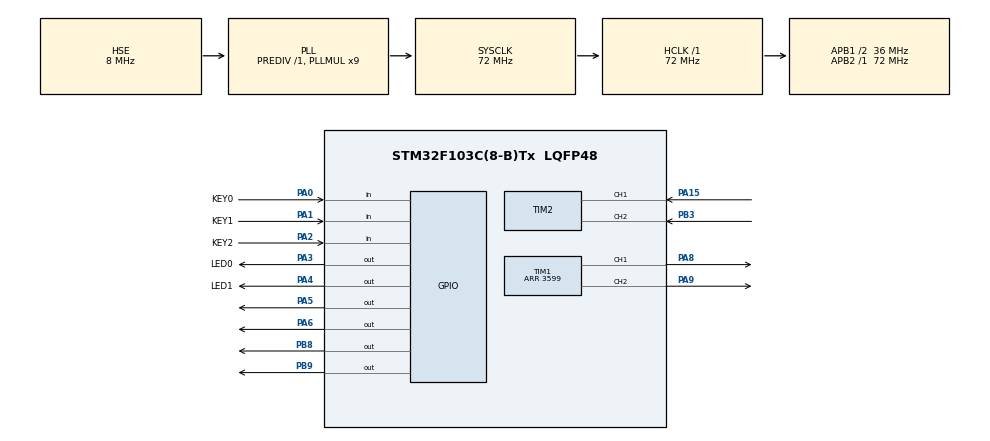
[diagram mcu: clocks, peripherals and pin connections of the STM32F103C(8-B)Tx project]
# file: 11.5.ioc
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Mcu.Family=STM32F1
Mcu.Name=STM32F103C(8-B)Tx
Mcu.Package=LQFP48
NVIC.PriorityGroup=NVIC_PRIORITYGROUP_4
NVIC.TIM3_IRQn=true\:0\:0\:false\:false\:true\:true\:true\:true
NVIC.TIM4_IRQn=true\:1\:0\:true\:false\:true\:true\:true\:true
PA0-WKUP.GPIO_Label=KEY0
PA0-WKUP.GPIO_PuPd=GPIO_PULLUP
PA0-WKUP.Signal=GPIO_Input
PA1.GPIO_Label=KEY1
PA1.GPIO_PuPd=GPIO_PULLUP
PA1.Signal=GPIO_Input
PA13.Mode=Serial_Wire
PA13.Signal=SYS_JTMS-SWDIO
PA14.Mode=Serial_Wire
PA14.Signal=SYS_JTCK-SWCLK
PA15.Signal=S_TIM2_CH1_ETR
PA2.GPIO_Label=KEY2
PA2.GPIO_PuPd=GPIO_PULLUP
PA2.Signal=GPIO_Input
PA3.GPIO_Label=LED0
PA3.PinState=GPIO_PIN_SET
PA3.Signal=GPIO_Output
PA4.GPIO_Label=LED1
PA4.PinState=GPIO_PIN_SET
PA4.Signal=GPIO_Output
PA5.Signal=GPIO_Output
PA6.Signal=GPIO_Output
PA8.Signal=S_TIM1_CH1
PA9.Signal=S_TIM1_CH2
PB3.Signal=S_TIM2_CH2
PB8.GPIO_ModeDefaultOutputPP=GPIO_MODE_OUTPUT_OD
PB8.GPIO_PuPd=GPIO_NOPULL
PB8.GPIO_Speed=GPIO_SPEED_FREQ_LOW
PB8.PinState=GPIO_PIN_SET
PB8.Signal=GPIO_Output
PB9.GPIO_ModeDefaultOutputPP=GPIO_MODE_OUTPUT_OD
PB9.GPIO_PuPd=GPIO_NOPULL
PB9.GPIO_Speed=GPIO_SPEED_FREQ_LOW
PB9.PinState=GPIO_PIN_SET
PB9.Signal=GPIO_Output
PC14-OSC32_IN.Mode=LSE-External-Oscillator
PC14-OSC32_IN.Signal=RCC_OSC32_IN
PC15-OSC32_OUT.Mode=LSE-External-Oscillator
PC15-OSC32_OUT.Signal=RCC_OSC32_OUT
PD0-OSC_IN.Mode=HSE-External-Oscillator
PD0-OSC_IN.Signal=RCC_OSC_IN
PD1-OSC_OUT.Mode=HSE-External-Oscillator
PD1-OSC_OUT.Signal=RCC_OSC_OUT
ProjectManager.HeapSize=0x200
ProjectManager.StackSize=0x400
ProjectManager.TargetToolchain=CMake
RCC.AHBFreq_Value=72000000
RCC.APB1CLKDivider=RCC_HCLK_DIV2
RCC.APB1Freq_Value=36000000
RCC.APB1TimFreq_Value=72000000
RCC.APB2Freq_Value=72000000
RCC.APB2TimFreq_Value=72000000
RCC.HCLKFreq_Value=72000000
RCC.PLLMUL=RCC_PLL_MUL9
RCC.PLLSourceVirtual=RCC_PLLSOURCE_HSE
RCC.SYSCLKFreq_VALUE=72000000
RCC.SYSCLKSource=RCC_SYSCLKSOURCE_PLLCLK
RCC.USBFreq_Value=72000000
SH.S_TIM1_CH1.0=TIM1_CH1,PWM Generation1 CH1
SH.S_TIM1_CH2.0=TIM1_CH2,PWM Generation2 CH2
SH.S_TIM2_CH1_ETR.0=TIM2_CH1,Encoder_Interface
SH.S_TIM2_CH2.0=TIM2_CH2,Encoder_Interface
TIM1.AutoReloadPreload=TIM_AUTORELOAD_PRELOAD_ENABLE
TIM1.Channel-PWM\ Generation1\ CH1=TIM_CHANNEL_1
TIM1.Channel-PWM\ Generation2\ CH2=TIM_CHANNEL_2
TIM1.Period=3599
TIM2.EncoderMode=TIM_ENCODERMODE_TI12
TIM2.IC1Filter=6
TIM3.AutoReloadPreload=TIM_AUTORELOAD_PRELOAD_ENABLE
TIM4.Period=99
TIM4.Prescaler=719
VP_TIM1_VS_ClockSourceINT.Mode=Internal
VP_TIM3_VS_ClockSourceINT.Mode=Internal
VP_TIM4_VS_ClockSourceINT.Mode=Internal
board=custom

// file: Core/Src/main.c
/* USER CODE BEGIN Header */
/**
  ******************************************************************************
  * @file           : main.c
  * @brief          : Main program body
  ******************************************************************************
  * @attention
  *
  * Copyright (c) 2026 STMicroelectronics.
  * All rights reserved.
  *
  * This software is licensed under terms that can be found in the LICENSE file
  * in the root directory of this software component.
  * If no LICENSE file comes with this software, it is provided AS-IS.
  *
  ******************************************************************************
  */
/* USER CODE END Header */
#include "main.h"

TIM_HandleTypeDef htim1;
TIM_HandleTypeDef htim2;
TIM_HandleTypeDef htim3;
TIM_HandleTypeDef htim4;

void SystemClock_Config(void);
static void MX_GPIO_Init(void);
static void MX_TIM1_Init(void);
static void MX_TIM2_Init(void);
static void MX_TIM4_Init(void);
static void MX_TIM3_Init(void);
/* USER CODE BEGIN PFP */
void appMain(void);
/* USER CODE END PFP */

int main(void)
{

  /* MCU Configuration--------------------------------------------------------*/

  /* Reset of all peripherals, Initializes the Flash interface and the Systick. */
  HAL_Init();

  /* Configure the system clock */
  SystemClock_Config();

  /* Initialize all configured peripherals */
  MX_GPIO_Init();
  MX_TIM1_Init();
  MX_TIM2_Init();
  MX_TIM4_Init();
  MX_TIM3_Init();
  /* USER CODE BEGIN 2 */
  appMain();
  /* USER CODE END 2 */

  /* Infinite loop */
  while (1)
  {

  }
}

void SystemClock_Config(void)
{
  RCC_OscInitTypeDef RCC_OscInitStruct = {0};
  RCC_ClkInitTypeDef RCC_ClkInitStruct = {0};

  /** Initializes the RCC Oscillators according to the specified parameters
  * in the RCC_OscInitTypeDef structure.
  */
  RCC_OscInitStruct.OscillatorType = RCC_OSCILLATORTYPE_HSE;
  RCC_OscInitStruct.HSEState = RCC_HSE_ON;
  RCC_OscInitStruct.HSEPredivValue = RCC_HSE_PREDIV_DIV1;
  RCC_OscInitStruct.HSIState = RCC_HSI_ON;
  RCC_OscInitStruct.PLL.PLLState = RCC_PLL_ON;
  RCC_OscInitStruct.PLL.PLLSource = RCC_PLLSOURCE_HSE;
  RCC_OscInitStruct.PLL.PLLMUL = RCC_PLL_MUL9;
  if (HAL_RCC_OscConfig(&RCC_OscInitStruct) != HAL_OK)
  {
    Error_Handler();
  }

  /** Initializes the CPU, AHB and APB buses clocks
  */
  RCC_ClkInitStruct.ClockType = RCC_CLOCKTYPE_HCLK|RCC_CLOCKTYPE_SYSCLK
                              |RCC_CLOCKTYPE_PCLK1|RCC_CLOCKTYPE_PCLK2;
  RCC_ClkInitStruct.SYSCLKSource = RCC_SYSCLKSOURCE_PLLCLK;
  RCC_ClkInitStruct.AHBCLKDivider = RCC_SYSCLK_DIV1;
  RCC_ClkInitStruct.APB1CLKDivider = RCC_HCLK_DIV2;
  RCC_ClkInitStruct.APB2CLKDivider = RCC_HCLK_DIV1;

  if (HAL_RCC_ClockConfig(&RCC_ClkInitStruct, FLASH_LATENCY_2) != HAL_OK)
  {
    Error_Handler();
  }
}

static void MX_TIM1_Init(void)
{

  TIM_ClockConfigTypeDef sClockSourceConfig = {0};
  TIM_MasterConfigTypeDef sMasterConfig = {0};
  TIM_OC_InitTypeDef sConfigOC = {0};
  TIM_BreakDeadTimeConfigTypeDef sBreakDeadTimeConfig = {0};

  htim1.Instance = TIM1;
  htim1.Init.Prescaler = 0;
  htim1.Init.CounterMode = TIM_COUNTERMODE_UP;
  htim1.Init.Period = 3599;
  htim1.Init.ClockDivision = TIM_CLOCKDIVISION_DIV1;
  htim1.Init.RepetitionCounter = 0;
  htim1.Init.AutoReloadPreload = TIM_AUTORELOAD_PRELOAD_ENABLE;
  if (HAL_TIM_Base_Init(&htim1) != HAL_OK)
  {
    Error_Handler();
  }
  sClockSourceConfig.ClockSource = TIM_CLOCKSOURCE_INTERNAL;
  if (HAL_TIM_ConfigClockSource(&htim1, &sClockSourceConfig) != HAL_OK)
  {
    Error_Handler();
  }
  if (HAL_TIM_PWM_Init(&htim1) != HAL_OK)
  {
    Error_Handler();
  }
  sMasterConfig.MasterOutputTrigger = TIM_TRGO_RESET;
  sMasterConfig.MasterSlaveMode = TIM_MASTERSLAVEMODE_DISABLE;
  if (HAL_TIMEx_MasterConfigSynchronization(&htim1, &sMasterConfig) != HAL_OK)
  {
    Error_Handler();
  }
  sConfigOC.OCMode = TIM_OCMODE_PWM1;
  sConfigOC.Pulse = 0;
  sConfigOC.OCPolarity = TIM_OCPOLARITY_HIGH;
  sConfigOC.OCNPolarity = TIM_OCNPOLARITY_HIGH;
  sConfigOC.OCFastMode = TIM_OCFAST_DISABLE;
  sConfigOC.OCIdleState = TIM_OCIDLESTATE_RESET;
  sConfigOC.OCNIdleState = TIM_OCNIDLESTATE_RESET;
  if (HAL_TIM_PWM_ConfigChannel(&htim1, &sConfigOC, TIM_CHANNEL_1) != HAL_OK)
  {
    Error_Handler();
  }
  if (HAL_TIM_PWM_ConfigChannel(&htim1, &sConfigOC, TIM_CHANNEL_2) != HAL_OK)
  {
    Error_Handler();
  }
  sBreakDeadTimeConfig.OffStateRunMode = TIM_OSSR_DISABLE;
  sBreakDeadTimeConfig.OffStateIDLEMode = TIM_OSSI_DISABLE;
  sBreakDeadTimeConfig.LockLevel = TIM_LOCKLEVEL_OFF;
  sBreakDeadTimeConfig.DeadTime = 0;
  sBreakDeadTimeConfig.BreakState = TIM_BREAK_DISABLE;
  sBreakDeadTimeConfig.BreakPolarity = TIM_BREAKPOLARITY_HIGH;
  sBreakDeadTimeConfig.AutomaticOutput = TIM_AUTOMATICOUTPUT_DISABLE;
  if (HAL_TIMEx_ConfigBreakDeadTime(&htim1, &sBreakDeadTimeConfig) != HAL_OK)
  {
    Error_Handler();
  }
  HAL_TIM_MspPostInit(&htim1);

}

static void MX_TIM2_Init(void)
{

  TIM_Encoder_InitTypeDef sConfig = {0};
  TIM_MasterConfigTypeDef sMasterConfig = {0};

  htim2.Instance = TIM2;
  htim2.Init.Prescaler = 0;
  htim2.Init.CounterMode = TIM_COUNTERMODE_UP;
  htim2.Init.Period = 65535;
  htim2.Init.ClockDivision = TIM_CLOCKDIVISION_DIV1;
  htim2.Init.AutoReloadPreload = TIM_AUTORELOAD_PRELOAD_DISABLE;
  sConfig.EncoderMode = TIM_ENCODERMODE_TI12;
  sConfig.IC1Polarity = TIM_ICPOLARITY_RISING;
  sConfig.IC1Selection = TIM_ICSELECTION_DIRECTTI;
  sConfig.IC1Prescaler = TIM_ICPSC_DIV1;
  sConfig.IC1Filter = 6;
  sConfig.IC2Polarity = TIM_ICPOLARITY_RISING;
  sConfig.IC2Selection = TIM_ICSELECTION_DIRECTTI;
  sConfig.IC2Prescaler = TIM_ICPSC_DIV1;
  sConfig.IC2Filter = 0;
  if (HAL_TIM_Encoder_Init(&htim2, &sConfig) != HAL_OK)
  {
    Error_Handler();
  }
  sMasterConfig.MasterOutputTrigger = TIM_TRGO_RESET;
  sMasterConfig.MasterSlaveMode = TIM_MASTERSLAVEMODE_DISABLE;
  if (HAL_TIMEx_MasterConfigSynchronization(&htim2, &sMasterConfig) != HAL_OK)
  {
    Error_Handler();
  }

}

static void MX_TIM3_Init(void)
{

  TIM_ClockConfigTypeDef sClockSourceConfig = {0};
  TIM_MasterConfigTypeDef sMasterConfig = {0};

  htim3.Instance = TIM3;
  htim3.Init.Prescaler = 0;
  htim3.Init.CounterMode = TIM_COUNTERMODE_UP;
  htim3.Init.Period = 65535;
  htim3.Init.ClockDivision = TIM_CLOCKDIVISION_DIV1;
  htim3.Init.AutoReloadPreload = TIM_AUTORELOAD_PRELOAD_ENABLE;
  if (HAL_TIM_Base_Init(&htim3) != HAL_OK)
  {
    Error_Handler();
  }
  sClockSourceConfig.ClockSource = TIM_CLOCKSOURCE_INTERNAL;
  if (HAL_TIM_ConfigClockSource(&htim3, &sClockSourceConfig) != HAL_OK)
  {
    Error_Handler();
  }
  sMasterConfig.MasterOutputTrigger = TIM_TRGO_RESET;
  sMasterConfig.MasterSlaveMode = TIM_MASTERSLAVEMODE_DISABLE;
  if (HAL_TIMEx_MasterConfigSynchronization(&htim3, &sMasterConfig) != HAL_OK)
  {
    Error_Handler();
  }

}

static void MX_TIM4_Init(void)
{

  TIM_ClockConfigTypeDef sClockSourceConfig = {0};
  TIM_MasterConfigTypeDef sMasterConfig = {0};

  htim4.Instance = TIM4;
  htim4.Init.Prescaler = 719;
  htim4.Init.CounterMode = TIM_COUNTERMODE_UP;
  htim4.Init.Period = 99;
  htim4.Init.ClockDivision = TIM_CLOCKDIVISION_DIV1;
  htim4.Init.AutoReloadPreload = TIM_AUTORELOAD_PRELOAD_DISABLE;
  if (HAL_TIM_Base_Init(&htim4) != HAL_OK)
  {
    Error_Handler();
  }
  sClockSourceConfig.ClockSource = TIM_CLOCKSOURCE_INTERNAL;
  if (HAL_TIM_ConfigClockSource(&htim4, &sClockSourceConfig) != HAL_OK)
  {
    Error_Handler();
  }
  sMasterConfig.MasterOutputTrigger = TIM_TRGO_RESET;
  sMasterConfig.MasterSlaveMode = TIM_MASTERSLAVEMODE_DISABLE;
  if (HAL_TIMEx_MasterConfigSynchronization(&htim4, &sMasterConfig) != HAL_OK)
  {
    Error_Handler();
  }

}

static void MX_GPIO_Init(void)
{
  GPIO_InitTypeDef GPIO_InitStruct = {0};

  /* GPIO Ports Clock Enable */
  __HAL_RCC_GPIOC_CLK_ENABLE();
  __HAL_RCC_GPIOD_CLK_ENABLE();
  __HAL_RCC_GPIOA_CLK_ENABLE();
  __HAL_RCC_GPIOB_CLK_ENABLE();

  /*Configure GPIO pin Output Level */
  HAL_GPIO_WritePin(GPIOA, LED0_Pin|LED1_Pin, GPIO_PIN_SET);

  /*Configure GPIO pin Output Level */
  HAL_GPIO_WritePin(GPIOA, GPIO_PIN_5|GPIO_PIN_6, GPIO_PIN_RESET);

  /*Configure GPIO pin Output Level */
  HAL_GPIO_WritePin(GPIOB, GPIO_PIN_8|GPIO_PIN_9, GPIO_PIN_SET);

  /*Configure GPIO pins : KEY0_Pin KEY1_Pin KEY2_Pin */
  GPIO_InitStruct.Pin = KEY0_Pin|KEY1_Pin|KEY2_Pin;
  GPIO_InitStruct.Mode = GPIO_MODE_INPUT;
  GPIO_InitStruct.Pull = GPIO_PULLUP;
  HAL_GPIO_Init(GPIOA, &GPIO_InitStruct);

  /*Configure GPIO pins : LED0_Pin LED1_Pin PA5 PA6 */
  GPIO_InitStruct.Pin = LED0_Pin|LED1_Pin|GPIO_PIN_5|GPIO_PIN_6;
  GPIO_InitStruct.Mode = GPIO_MODE_OUTPUT_PP;
  GPIO_InitStruct.Pull = GPIO_NOPULL;
  GPIO_InitStruct.Speed = GPIO_SPEED_FREQ_LOW;
  HAL_GPIO_Init(GPIOA, &GPIO_InitStruct);

  /*Configure GPIO pins : PB8 PB9 */
  GPIO_InitStruct.Pin = GPIO_PIN_8|GPIO_PIN_9;
  GPIO_InitStruct.Mode = GPIO_MODE_OUTPUT_OD;
  GPIO_InitStruct.Pull = GPIO_NOPULL;
  GPIO_InitStruct.Speed = GPIO_SPEED_FREQ_LOW;
  HAL_GPIO_Init(GPIOB, &GPIO_InitStruct);

}

void Error_Handler(void)
{
  __disable_irq();
  while (1)
  {
  }
}
